AUTOSAR XML (schema 4-2-2)
standard types defined: uint8
package /ASW_COM_Package
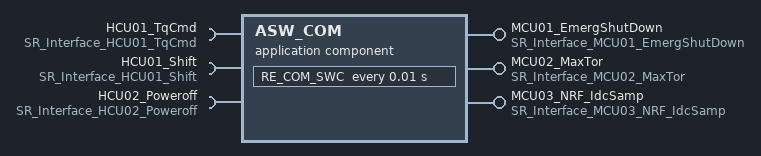
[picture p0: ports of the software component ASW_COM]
  application sw component type ASW_COM
    provide port MCU01_EmergShutDown: nonqueued-sender-com-spec=SR_Interface_MCU01_EmergShutDown/value, provided-interface=SR_Interface_MCU01_EmergShutDown
    provide port MCU02_MaxTor: nonqueued-sender-com-spec=SR_Interface_MCU02_MaxTor/value, provided-interface=SR_Interface_MCU02_MaxTor
    provide port MCU03_NRF_IdcSamp: nonqueued-sender-com-spec=SR_Interface_MCU03_NRF_IdcSamp/value, provided-interface=SR_Interface_MCU03_NRF_IdcSamp
    require port HCU01_TqCmd: nonqueued-receiver-com-spec{data-element=SR_Interface_HCU01_TqCmd/value, alive-timeout=0.3}, required-interface=SR_Interface_HCU01_TqCmd
    require port HCU01_Shift: nonqueued-receiver-com-spec{data-element=SR_Interface_HCU01_Shift/value, alive-timeout=0.3}, required-interface=SR_Interface_HCU01_Shift
    require port HCU02_Poweroff: nonqueued-receiver-com-spec{data-element=SR_Interface_HCU02_Poweroff/value, alive-timeout=0.3}, required-interface=SR_Interface_HCU02_Poweroff
    behavior IB_ASW_COM
      timing event TE_RE_COM_SWC_10ms: start-on-event=RE_COM_SWC, period=0.01
      runnable RE_COM_SWC
        data-read-accesses:
          access VA_READ_HCU01_TqCmd: accessed-variable=HCU01_TqCmd.value
          access VA_READ_HCU01_Shift: accessed-variable=HCU01_Shift.value
          access VA_READ_HCU02_Poweroff: accessed-variable=HCU02_Poweroff.value
        data-write-accesses:
          access VA_WRITE_MCU01_EmergShutDown: accessed-variable=MCU01_EmergShutDown.value
          access VA_WRITE_MCU02_MaxTor: accessed-variable=MCU02_MaxTor.value
          access VA_WRITE_MCU03_NRF_IdcSamp: accessed-variable=MCU03_NRF_IdcSamp.value
package /COM_Interface
  6 x sender receiver interface:
    SR_Interface_MCU01_EmergShutDown
      data value: type=uint8
    SR_Interface_MCU02_MaxTor
      data value: type=uint8
    SR_Interface_MCU03_NRF_IdcSamp
      data value: type=uint8
    SR_Interface_HCU01_TqCmd
      data value: type=uint8
    SR_Interface_HCU01_Shift
      data value: type=uint8
    SR_Interface_HCU02_Poweroff
      data value: type=uint8
